AUTOSAR XML (schema 00049)
package /Application/DltConfig
  dlt log channel to process mapping DltLogChannelToProcessMapping_MonitoringManager_TO_MonitoringManager: dlt-log-channel=MonitoringManager, process=MonitoringManager
package /Application/Executable
  executable MonitoringManager: category=APPLICATION_LEVEL, logging-behavior=USES-LOGGING, reporting-behavior=REPORTS-EXECUTION-STATE, version=1.0.0
    root sw component prototype AA: application-type=MonitoringManager
package /Application/Manifest
  14 x service instance to port prototype mapping:
    MonitoringManager_AA_PPortMonitoringManagement: port-prototype=AA.PPortMonitoringManagement, service-instance=EEVP_MonitoringManager_Provider_MonitoringManagement
    MonitoringManager_AA_RPortDms: port-prototype=AA.RPortDms, service-instance=EEVP_MonitoringManager_Consumer_Dms
    MonitoringManager_AA_RPortDrvSeat: port-prototype=AA.RPortDrvSeat, service-instance=EEVP_MonitoringManager_Consumer_SoaDriverSeat
    MonitoringManager_AA_RPortHvac: port-prototype=AA.RPortHvac, service-instance=EEVP_MonitoringManager_Consumer_Hvac
    MonitoringManager_AA_RPortMoodLamp: port-prototype=AA.RPortMoodLamp, service-instance=EEVP_MonitoringManager_Consumer_MoodLamp
    MonitoringManager_AA_RPortOtaMonitoring: port-prototype=AA.RPortOtaMonitoring, service-instance=EEVP_MonitoringManager_Consumer_OtaMonitoring
    MonitoringManager_AA_RPortPDW: port-prototype=AA.RPortPDWFront, service-instance=EEVP_MonitoringManager_Consumer_PDWFront
    MonitoringManager_AA_RPortPDWRear: port-prototype=AA.RPortPDWRear, service-instance=EEVP_MonitoringManager_Consumer_PDWRear
    MonitoringManager_AA_RPortPower: port-prototype=AA.RPortPower, service-instance=EEVP_MonitoringManager_Consumer_SoaPower
    MonitoringManager_AA_RPortRearCurtain: port-prototype=AA.RPortRearCurtain, service-instance=EEVP_MonitoringManager_Consumer_RearCurtain
    MonitoringManager_AA_RPortRoa: port-prototype=AA.RPortRoa, service-instance=EEVP_MonitoringManager_Consumer_SoaRoa
    MonitoringManager_AA_RPortSmartFilm: port-prototype=AA.RPortSmartFilm, service-instance=EEVP_MonitoringManager_Consumer_SmartFilm
    MonitoringManager_AA_RPortStateManager: port-prototype=AA.RPortStateManager, service-instance=EEVP_MonitoringManager_Consumer_StateManager
    MonitoringManager_AA_RPortWiper: port-prototype=AA.RPortWiper, service-instance=EEVP_MonitoringManager_Consumer_Wiper
package /Application/Process
  process MonitoringManager: executable=MonitoringManager, state-dependent-startup-config{execution-dependency=OTAClient.Running, function-group-state=MachineFG.Startup, resource-group=DefaultResourceGroup, startup-config=MonitoringManager}
    process state machine MonitoringManager: type=ProcessState
package /Application/StartupConfig
  startup config set EEVP_MonitoringManager_StartupConfig
    startup config MonitoringManager: scheduling-policy=SCHED_OTHER, scheduling-priority=0, timeout={enter-timeout-value=2.0, exit-timeout-value=2.0}
package /Application/SwComponent
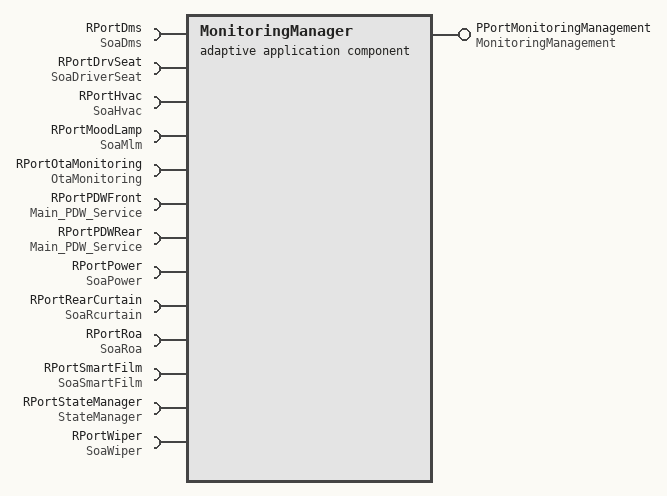
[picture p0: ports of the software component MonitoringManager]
  adaptive application sw component type MonitoringManager
    provide port PPortMonitoringManagement: provided-interface=MonitoringManagement
    13 x require port:
      RPortDms: required-interface=SoaDms
      RPortDrvSeat: required-interface=SoaDriverSeat
      RPortHvac: required-interface=SoaHvac
      RPortMoodLamp: required-interface=SoaMlm
      RPortOtaMonitoring: required-interface=OtaMonitoring
      RPortPDWFront: required-interface=Main_PDW_Service
      RPortPDWRear: required-interface=Main_PDW_Service
      RPortPower: required-interface=SoaPower
      RPortRearCurtain: required-interface=SoaRcurtain
      RPortRoa: required-interface=SoaRoa
      RPortSmartFilm: required-interface=SoaSmartFilm
      RPortStateManager: required-interface=StateManager
      RPortWiper: required-interface=SoaWiper
